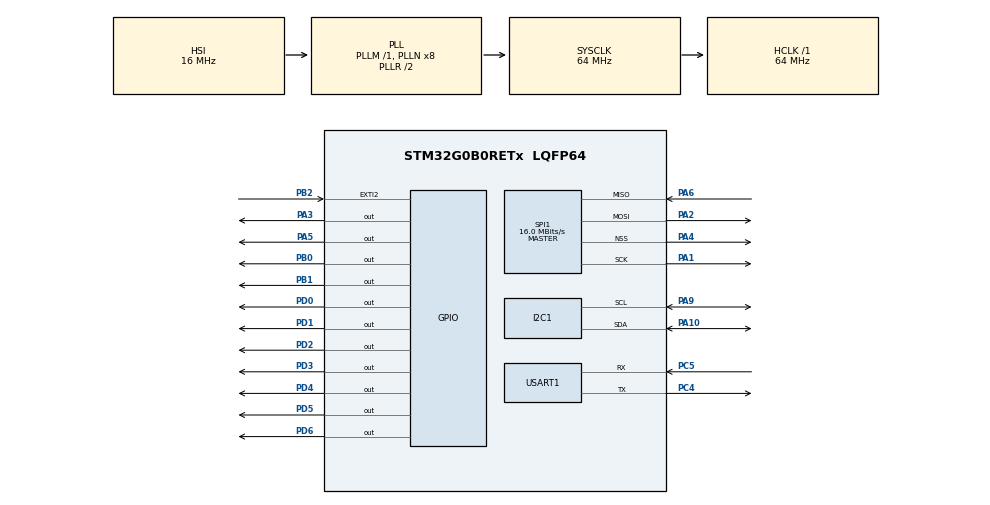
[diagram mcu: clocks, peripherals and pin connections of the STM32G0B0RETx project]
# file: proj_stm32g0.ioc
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Dma.MEMTOMEM.1.Direction=DMA_MEMORY_TO_MEMORY
Dma.MEMTOMEM.1.EventEnable=DISABLE
Dma.MEMTOMEM.1.Instance=DMA2_Channel5
Dma.MEMTOMEM.1.MemDataAlignment=DMA_MDATAALIGN_WORD
Dma.MEMTOMEM.1.MemInc=DMA_MINC_ENABLE
Dma.MEMTOMEM.1.Mode=DMA_NORMAL
Dma.MEMTOMEM.1.PeriphDataAlignment=DMA_PDATAALIGN_WORD
Dma.MEMTOMEM.1.PeriphInc=DMA_PINC_ENABLE
Dma.MEMTOMEM.1.Polarity=HAL_DMAMUX_REQ_GEN_RISING
Dma.MEMTOMEM.1.Priority=DMA_PRIORITY_MEDIUM
Dma.MEMTOMEM.1.RequestNumber=1
Dma.MEMTOMEM.1.SignalID=NONE
Dma.MEMTOMEM.1.SyncEnable=DISABLE
Dma.MEMTOMEM.1.SyncPolarity=HAL_DMAMUX_SYNC_NO_EVENT
Dma.MEMTOMEM.1.SyncRequestNumber=1
Dma.MEMTOMEM.1.SyncSignalID=NONE
Dma.Request0=SPI1_TX
Dma.Request1=MEMTOMEM
Dma.SPI1_TX.0.Direction=DMA_MEMORY_TO_PERIPH
Dma.SPI1_TX.0.EventEnable=DISABLE
Dma.SPI1_TX.0.Instance=DMA1_Channel1
Dma.SPI1_TX.0.MemDataAlignment=DMA_MDATAALIGN_BYTE
Dma.SPI1_TX.0.MemInc=DMA_MINC_ENABLE
Dma.SPI1_TX.0.Mode=DMA_NORMAL
Dma.SPI1_TX.0.PeriphDataAlignment=DMA_PDATAALIGN_BYTE
Dma.SPI1_TX.0.PeriphInc=DMA_PINC_DISABLE
Dma.SPI1_TX.0.Polarity=HAL_DMAMUX_REQ_GEN_RISING
Dma.SPI1_TX.0.Priority=DMA_PRIORITY_LOW
Dma.SPI1_TX.0.RequestNumber=1
Dma.SPI1_TX.0.SignalID=NONE
Dma.SPI1_TX.0.SyncEnable=DISABLE
Dma.SPI1_TX.0.SyncPolarity=HAL_DMAMUX_SYNC_NO_EVENT
Dma.SPI1_TX.0.SyncRequestNumber=1
Dma.SPI1_TX.0.SyncSignalID=NONE
I2C1.Timing=0x10B17DB5
Mcu.Family=STM32G0
Mcu.Name=STM32G0B0RETx
Mcu.Package=LQFP64
NVIC.DMA1_Channel1_IRQn=true\:0\:0\:false\:false\:true\:false\:true\:true
NVIC.EXTI2_3_IRQn=true\:0\:0\:false\:false\:true\:true\:true\:true
PA1.Mode=Full_Duplex_Master
PA1.Signal=SPI1_SCK
PA10.Mode=I2C
PA10.Signal=I2C1_SDA
PA2.Mode=Full_Duplex_Master
PA2.Signal=SPI1_MOSI
PA3.Signal=GPIO_Output
PA4.Mode=NSS_Signal_Hard_Output
PA4.Signal=SPI1_NSS
PA5.Signal=GPIO_Output
PA6.Mode=Full_Duplex_Master
PA6.Signal=SPI1_MISO
PA9.Mode=I2C
PA9.Signal=I2C1_SCL
PB0.Signal=GPIO_Output
PB1.Signal=GPIO_Output
PB2.GPIO_ModeDefaultEXTI=GPIO_MODE_IT_FALLING
PB2.GPIO_PuPd=GPIO_PULLUP
PB2.Signal=GPXTI2
PC4.Mode=Asynchronous
PC4.Signal=USART1_TX
PC5.Mode=Asynchronous
PC5.Signal=USART1_RX
PD0.GPIO_Speed=GPIO_SPEED_FREQ_HIGH
PD0.PinState=GPIO_PIN_RESET
PD0.Signal=GPIO_Output
PD1.GPIO_Speed=GPIO_SPEED_FREQ_HIGH
PD1.Signal=GPIO_Output
PD2.GPIO_Speed=GPIO_SPEED_FREQ_HIGH
PD2.Signal=GPIO_Output
PD3.GPIO_Speed=GPIO_SPEED_FREQ_HIGH
PD3.Signal=GPIO_Output
PD4.GPIO_Speed=GPIO_SPEED_FREQ_HIGH
PD4.Signal=GPIO_Output
PD5.GPIO_Speed=GPIO_SPEED_FREQ_HIGH
PD5.Signal=GPIO_Output
PD6.GPIO_Speed=GPIO_SPEED_FREQ_HIGH
PD6.Signal=GPIO_Output
ProjectManager.HeapSize=0x200
ProjectManager.StackSize=0x400
ProjectManager.TargetToolchain=STM32CubeIDE
RCC.ADCFreq_Value=64000000
RCC.AHBFreq_Value=64000000
RCC.CortexFreq_Value=64000000
RCC.EXTERNAL_CLOCK_VALUE=48000
RCC.HCLKFreq_Value=64000000
RCC.HSE_VALUE=8000000
RCC.HSI_VALUE=16000000
RCC.LSE_VALUE=32768
RCC.SYSCLKFreq_VALUE=64000000
RCC.SYSCLKSource=RCC_SYSCLKSOURCE_PLLCLK
RCC.USBFreq_Value=64000000
RCC.VCOOutputFreq_Value=128000000
SPI1.BaudRatePrescaler=SPI_BAUDRATEPRESCALER_4
SPI1.CLKPolarity=SPI_POLARITY_HIGH
SPI1.CalculateBaudRate=16.0 MBits/s
SPI1.Direction=SPI_DIRECTION_2LINES
SPI1.Mode=SPI_MODE_MASTER
SPI1.VirtualNSS=VM_NSSHARD
SPI1.VirtualType=VM_MASTER
USART1.VirtualMode-Asynchronous=VM_ASYNC
VP_SYS_VS_DBSignals.Mode=DisableDeadBatterySignals
board=custom

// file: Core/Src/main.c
/* USER CODE BEGIN Header */
/**
 ******************************************************************************
 * @file           : main.c
 * @brief          : Main program body
 ******************************************************************************
 * @attention
 *
 * Copyright (c) 2024 STMicroelectronics.
 * All rights reserved.
 *
 * This software is licensed under terms that can be found in the LICENSE file
 * in the root directory of this software component.
 * If no LICENSE file comes with this software, it is provided AS-IS.
 *
 ******************************************************************************
 */
/* USER CODE END Header */
#include "main.h"

/* USER CODE BEGIN Includes */
#include <stdio.h>
/* USER CODE END Includes */

I2C_HandleTypeDef hi2c1;

SPI_HandleTypeDef hspi1;
DMA_HandleTypeDef hdma_spi1_tx;

UART_HandleTypeDef huart1;

DMA_HandleTypeDef hdma_memtomem_dma2_channel5;

void SystemClock_Config(void);
static void MX_GPIO_Init(void);
static void MX_DMA_Init(void);
static void MX_USART1_UART_Init(void);
static void MX_SPI1_Init(void);
static void MX_I2C1_Init(void);

/* USER CODE BEGIN 0 */
int __io_putchar(int ch)
{
    HAL_UART_Transmit(&huart1, (uint8_t *)&ch, 1, HAL_MAX_DELAY);
    return ch;
}
/* USER CODE END 0 */

int main(void)
{

  /* MCU Configuration--------------------------------------------------------*/

  /* Reset of all peripherals, Initializes the Flash interface and the Systick. */
  HAL_Init();

  /* Configure the system clock */
  SystemClock_Config();

  /* Initialize all configured peripherals */
  MX_GPIO_Init();
  MX_DMA_Init();
  MX_USART1_UART_Init();
  MX_SPI1_Init();
  MX_I2C1_Init();
  /* USER CODE BEGIN 2 */
    extern void port_main(void);
    port_main();
  /* USER CODE END 2 */

  /* Infinite loop */
    while (1)
    {

    }
}

void SystemClock_Config(void)
{
  RCC_OscInitTypeDef RCC_OscInitStruct = {0};
  RCC_ClkInitTypeDef RCC_ClkInitStruct = {0};

  /** Configure the main internal regulator output voltage
  */
  HAL_PWREx_ControlVoltageScaling(PWR_REGULATOR_VOLTAGE_SCALE1);

  /** Initializes the RCC Oscillators according to the specified parameters
  * in the RCC_OscInitTypeDef structure.
  */
  RCC_OscInitStruct.OscillatorType = RCC_OSCILLATORTYPE_HSI;
  RCC_OscInitStruct.HSIState = RCC_HSI_ON;
  RCC_OscInitStruct.HSIDiv = RCC_HSI_DIV1;
  RCC_OscInitStruct.HSICalibrationValue = RCC_HSICALIBRATION_DEFAULT;
  RCC_OscInitStruct.PLL.PLLState = RCC_PLL_ON;
  RCC_OscInitStruct.PLL.PLLSource = RCC_PLLSOURCE_HSI;
  RCC_OscInitStruct.PLL.PLLM = RCC_PLLM_DIV1;
  RCC_OscInitStruct.PLL.PLLN = 8;
  RCC_OscInitStruct.PLL.PLLP = RCC_PLLP_DIV2;
  RCC_OscInitStruct.PLL.PLLQ = RCC_PLLQ_DIV2;
  RCC_OscInitStruct.PLL.PLLR = RCC_PLLR_DIV2;
  if (HAL_RCC_OscConfig(&RCC_OscInitStruct) != HAL_OK)
  {
    Error_Handler();
  }

  /** Initializes the CPU, AHB and APB buses clocks
  */
  RCC_ClkInitStruct.ClockType = RCC_CLOCKTYPE_HCLK|RCC_CLOCKTYPE_SYSCLK
                              |RCC_CLOCKTYPE_PCLK1;
  RCC_ClkInitStruct.SYSCLKSource = RCC_SYSCLKSOURCE_PLLCLK;
  RCC_ClkInitStruct.AHBCLKDivider = RCC_SYSCLK_DIV1;
  RCC_ClkInitStruct.APB1CLKDivider = RCC_HCLK_DIV1;

  if (HAL_RCC_ClockConfig(&RCC_ClkInitStruct, FLASH_LATENCY_2) != HAL_OK)
  {
    Error_Handler();
  }
}

static void MX_I2C1_Init(void)
{

  hi2c1.Instance = I2C1;
  hi2c1.Init.Timing = 0x10B17DB5;
  hi2c1.Init.OwnAddress1 = 0;
  hi2c1.Init.AddressingMode = I2C_ADDRESSINGMODE_7BIT;
  hi2c1.Init.DualAddressMode = I2C_DUALADDRESS_DISABLE;
  hi2c1.Init.OwnAddress2 = 0;
  hi2c1.Init.OwnAddress2Masks = I2C_OA2_NOMASK;
  hi2c1.Init.GeneralCallMode = I2C_GENERALCALL_DISABLE;
  hi2c1.Init.NoStretchMode = I2C_NOSTRETCH_DISABLE;
  if (HAL_I2C_Init(&hi2c1) != HAL_OK)
  {
    Error_Handler();
  }

  /** Configure Analogue filter
  */
  if (HAL_I2CEx_ConfigAnalogFilter(&hi2c1, I2C_ANALOGFILTER_ENABLE) != HAL_OK)
  {
    Error_Handler();
  }

  /** Configure Digital filter
  */
  if (HAL_I2CEx_ConfigDigitalFilter(&hi2c1, 0) != HAL_OK)
  {
    Error_Handler();
  }

}

static void MX_SPI1_Init(void)
{

  /* SPI1 parameter configuration*/
  hspi1.Instance = SPI1;
  hspi1.Init.Mode = SPI_MODE_MASTER;
  hspi1.Init.Direction = SPI_DIRECTION_2LINES;
  hspi1.Init.DataSize = SPI_DATASIZE_8BIT;
  hspi1.Init.CLKPolarity = SPI_POLARITY_HIGH;
  hspi1.Init.CLKPhase = SPI_PHASE_1EDGE;
  hspi1.Init.NSS = SPI_NSS_HARD_OUTPUT;
  hspi1.Init.BaudRatePrescaler = SPI_BAUDRATEPRESCALER_4;
  hspi1.Init.FirstBit = SPI_FIRSTBIT_MSB;
  hspi1.Init.TIMode = SPI_TIMODE_DISABLE;
  hspi1.Init.CRCCalculation = SPI_CRCCALCULATION_DISABLE;
  hspi1.Init.CRCPolynomial = 7;
  hspi1.Init.CRCLength = SPI_CRC_LENGTH_DATASIZE;
  hspi1.Init.NSSPMode = SPI_NSS_PULSE_ENABLE;
  if (HAL_SPI_Init(&hspi1) != HAL_OK)
  {
    Error_Handler();
  }

}

static void MX_USART1_UART_Init(void)
{

  huart1.Instance = USART1;
  huart1.Init.BaudRate = 115200;
  huart1.Init.WordLength = UART_WORDLENGTH_8B;
  huart1.Init.StopBits = UART_STOPBITS_1;
  huart1.Init.Parity = UART_PARITY_NONE;
  huart1.Init.Mode = UART_MODE_TX_RX;
  huart1.Init.HwFlowCtl = UART_HWCONTROL_NONE;
  huart1.Init.OverSampling = UART_OVERSAMPLING_16;
  huart1.Init.OneBitSampling = UART_ONE_BIT_SAMPLE_DISABLE;
  huart1.Init.ClockPrescaler = UART_PRESCALER_DIV1;
  huart1.AdvancedInit.AdvFeatureInit = UART_ADVFEATURE_NO_INIT;
  if (HAL_UART_Init(&huart1) != HAL_OK)
  {
    Error_Handler();
  }
  if (HAL_UARTEx_SetTxFifoThreshold(&huart1, UART_TXFIFO_THRESHOLD_1_8) != HAL_OK)
  {
    Error_Handler();
  }
  if (HAL_UARTEx_SetRxFifoThreshold(&huart1, UART_RXFIFO_THRESHOLD_1_8) != HAL_OK)
  {
    Error_Handler();
  }
  if (HAL_UARTEx_DisableFifoMode(&huart1) != HAL_OK)
  {
    Error_Handler();
  }

}

static void MX_DMA_Init(void)
{

  /* DMA controller clock enable */
  __HAL_RCC_DMA1_CLK_ENABLE();
  __HAL_RCC_DMA2_CLK_ENABLE();

  /* Configure DMA request hdma_memtomem_dma2_channel5 on DMA2_Channel5 */
  hdma_memtomem_dma2_channel5.Instance = DMA2_Channel5;
  hdma_memtomem_dma2_channel5.Init.Request = DMA_REQUEST_MEM2MEM;
  hdma_memtomem_dma2_channel5.Init.Direction = DMA_MEMORY_TO_MEMORY;
  hdma_memtomem_dma2_channel5.Init.PeriphInc = DMA_PINC_ENABLE;
  hdma_memtomem_dma2_channel5.Init.MemInc = DMA_MINC_ENABLE;
  hdma_memtomem_dma2_channel5.Init.PeriphDataAlignment = DMA_PDATAALIGN_WORD;
  hdma_memtomem_dma2_channel5.Init.MemDataAlignment = DMA_MDATAALIGN_WORD;
  hdma_memtomem_dma2_channel5.Init.Mode = DMA_NORMAL;
  hdma_memtomem_dma2_channel5.Init.Priority = DMA_PRIORITY_MEDIUM;
  if (HAL_DMA_Init(&hdma_memtomem_dma2_channel5) != HAL_OK)
  {
    Error_Handler( );
  }

  /* DMA interrupt init */
  /* DMA1_Channel1_IRQn interrupt configuration */
  HAL_NVIC_SetPriority(DMA1_Channel1_IRQn, 0, 0);
  HAL_NVIC_EnableIRQ(DMA1_Channel1_IRQn);

}

static void MX_GPIO_Init(void)
{
  GPIO_InitTypeDef GPIO_InitStruct = {0};

  /* GPIO Ports Clock Enable */
  __HAL_RCC_GPIOA_CLK_ENABLE();
  __HAL_RCC_GPIOC_CLK_ENABLE();
  __HAL_RCC_GPIOB_CLK_ENABLE();
  __HAL_RCC_GPIOD_CLK_ENABLE();

  /*Configure GPIO pin Output Level */
  HAL_GPIO_WritePin(GPIOA, GPIO_PIN_3|GPIO_PIN_5, GPIO_PIN_RESET);

  /*Configure GPIO pin Output Level */
  HAL_GPIO_WritePin(GPIOB, GPIO_PIN_0|GPIO_PIN_1, GPIO_PIN_RESET);

  /*Configure GPIO pin Output Level */
  HAL_GPIO_WritePin(GPIOD, GPIO_PIN_0|GPIO_PIN_1|GPIO_PIN_2|GPIO_PIN_3
                          |GPIO_PIN_4|GPIO_PIN_5|GPIO_PIN_6, GPIO_PIN_RESET);

  /*Configure GPIO pins : PA3 PA5 */
  GPIO_InitStruct.Pin = GPIO_PIN_3|GPIO_PIN_5;
  GPIO_InitStruct.Mode = GPIO_MODE_OUTPUT_PP;
  GPIO_InitStruct.Pull = GPIO_NOPULL;
  GPIO_InitStruct.Speed = GPIO_SPEED_FREQ_LOW;
  HAL_GPIO_Init(GPIOA, &GPIO_InitStruct);

  /*Configure GPIO pins : PB0 PB1 */
  GPIO_InitStruct.Pin = GPIO_PIN_0|GPIO_PIN_1;
  GPIO_InitStruct.Mode = GPIO_MODE_OUTPUT_PP;
  GPIO_InitStruct.Pull = GPIO_NOPULL;
  GPIO_InitStruct.Speed = GPIO_SPEED_FREQ_LOW;
  HAL_GPIO_Init(GPIOB, &GPIO_InitStruct);

  /*Configure GPIO pin : PB2 */
  GPIO_InitStruct.Pin = GPIO_PIN_2;
  GPIO_InitStruct.Mode = GPIO_MODE_IT_FALLING;
  GPIO_InitStruct.Pull = GPIO_PULLUP;
  HAL_GPIO_Init(GPIOB, &GPIO_InitStruct);

  /*Configure GPIO pins : PD0 PD1 PD2 PD3
                           PD4 PD5 PD6 */
  GPIO_InitStruct.Pin = GPIO_PIN_0|GPIO_PIN_1|GPIO_PIN_2|GPIO_PIN_3
                          |GPIO_PIN_4|GPIO_PIN_5|GPIO_PIN_6;
  GPIO_InitStruct.Mode = GPIO_MODE_OUTPUT_PP;
  GPIO_InitStruct.Pull = GPIO_NOPULL;
  GPIO_InitStruct.Speed = GPIO_SPEED_FREQ_HIGH;
  HAL_GPIO_Init(GPIOD, &GPIO_InitStruct);

  /* EXTI interrupt init*/
  HAL_NVIC_SetPriority(EXTI2_3_IRQn, 0, 0);
  HAL_NVIC_EnableIRQ(EXTI2_3_IRQn);

}

void Error_Handler(void)
{
    __disable_irq();
    while (1)
    {
    }
}
